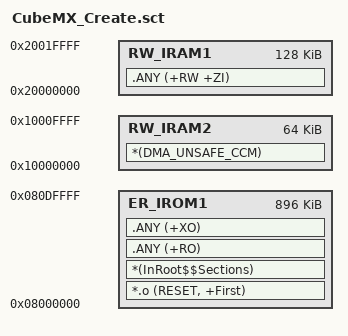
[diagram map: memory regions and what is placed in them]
; *************************************************************
; *** Scatter-Loading Description File generated by uVision ***
; *************************************************************

; Sector 11 (0x080E0000..0x080FFFFF) reserved for configuration records.
LR_IROM1 0x08000000 0x000E0000  {    ; load region size_region
  ER_IROM1 0x08000000 0x000E0000  {  ; load address = execution address
   *.o (RESET, +First)
   *(InRoot$$Sections)
   .ANY (+RO)
   .ANY (+XO)
  }
  RW_IRAM1 0x20000000 0x00020000  {  ; RW data
   .ANY (+RW +ZI)
  }
  RW_IRAM2 0x10000000 0x00010000  {
   *(DMA_UNSAFE_CCM)
  }
}

